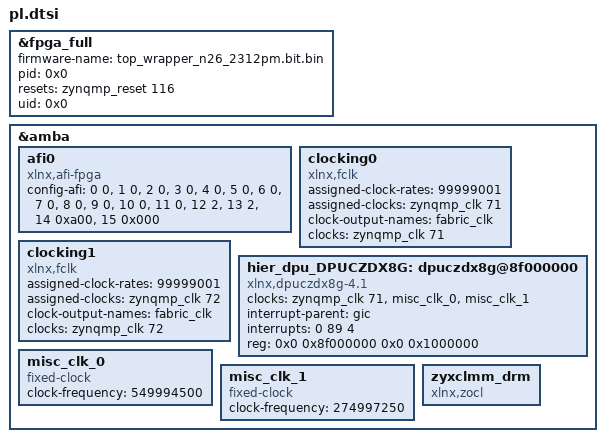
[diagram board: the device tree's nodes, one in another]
/*
 * CAUTION: This file is automatically generated by Xilinx.
 * Version: XSCT 
 * Today is: Mon Nov 27 20:20:20 2023
 */


/dts-v1/;
/plugin/;
/ {
	fragment@0 {
		target = <&fpga_full>;
		overlay0: __overlay__ {
			#address-cells = <2>;
			#size-cells = <2>;
			firmware-name = "top_wrapper_n26_2312pm.bit.bin";
			pid = <0x0>;
			resets = <&zynqmp_reset 116>;
			uid = <0x0>;
		};
	};
	fragment@1 {
		target = <&amba>;
		overlay1: __overlay__ {
			afi0: afi0 {
				compatible = "xlnx,afi-fpga";
				config-afi = < 0 0>, <1 0>, <2 0>, <3 0>, <4 0>, <5 0>, <6 0>, <7 0>, <8 0>, <9 0>, <10 0>, <11 0>, <12 2>, <13 2>, <14 0xa00>, <15 0x000>;
			};
			clocking0: clocking0 {
				#clock-cells = <0>;
				assigned-clock-rates = <99999001>;
				assigned-clocks = <&zynqmp_clk 71>;
				clock-output-names = "fabric_clk";
				clocks = <&zynqmp_clk 71>;
				compatible = "xlnx,fclk";
			};
			clocking1: clocking1 {
				#clock-cells = <0>;
				assigned-clock-rates = <99999001>;
				assigned-clocks = <&zynqmp_clk 72>;
				clock-output-names = "fabric_clk";
				clocks = <&zynqmp_clk 72>;
				compatible = "xlnx,fclk";
			};
		};
	};
	fragment@2 {
		target = <&amba>;
		overlay2: __overlay__ {
			#address-cells = <2>;
			#size-cells = <2>;
			hier_dpu_DPUCZDX8G: dpuczdx8g@8f000000 {
				clock-names = "s_axi_aclk", "dpu_2x_clk", "m_axi_dpu_aclk";
				clocks = <&zynqmp_clk 71>, <&misc_clk_0>, <&misc_clk_1>;
				compatible = "xlnx,dpuczdx8g-4.1";
				interrupt-names = "dpu0_interrupt";
				interrupt-parent = <&gic>;
				interrupts = <0 89 4>;
				reg = <0x0 0x8f000000 0x0 0x1000000>;
			};
			misc_clk_0: misc_clk_0 {
				#clock-cells = <0>;
				clock-frequency = <549994500>;
				compatible = "fixed-clock";
			};
			misc_clk_1: misc_clk_1 {
				#clock-cells = <0>;
				clock-frequency = <274997250>;
				compatible = "fixed-clock";
			};
			zyxclmm_drm {
				compatible = "xlnx,zocl";
			};
		};
	};
};
